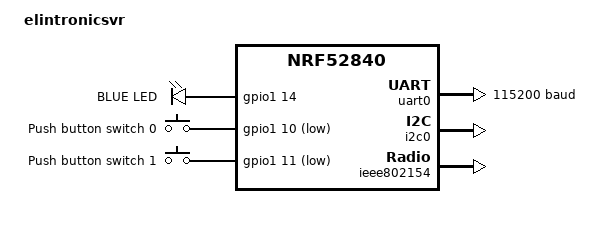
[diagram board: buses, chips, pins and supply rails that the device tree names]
// Copyright (c) 2023 Nordic Semiconductor ASA
// SPDX-License-Identifier: Apache-2.0

/dts-v1/;
#include <nordic/nrf52840_qiaa.dtsi>
#include "elintronicsvr-pinctrl.dtsi"

/ {
	model = "elintronicsvr";
	compatible = "elintronicsvr";

	chosen {
		zephyr,sram = &sram0;
		zephyr,flash = &flash0;
		zephyr,code-partition = &slot0_partition;
		zephyr,console = &uart0;
		zephyr,shell-uart = &uart0;
		zephyr,uart-mcumgr = &uart0;
		zephyr,bt-mon-uart = &uart0;
		zephyr,bt-c2h-uart = &uart0;
		zephyr,ieee802154 = &ieee802154;
	};

	leds {
		compatible = "gpio-leds";
		ledblue: led_0 {
			gpios = <&gpio1 14 0>;
			label = "BLUE LED";
		};
	};

	buttons {
		compatible = "gpio-keys";
		button0: button_0 {
			gpios = <&gpio1 10 (GPIO_PULL_UP | GPIO_ACTIVE_LOW)>;
			label = "Push button switch 0";
		};
		button1: button_1 {
			gpios = <&gpio1 11 (GPIO_PULL_UP | GPIO_ACTIVE_LOW)>;
			label = "Push button switch 1";
		};
	};

	aliases {
		ledblue = &ledblue;	
		button0 = &button0;	
	};
};

&gpiote {
	status = "okay";
};

&gpio0 {
	status = "okay";
};

&gpio1 {
	status = "okay";
};

&uart0 {
	compatible = "nordic,nrf-uarte";
	status = "okay";
	current-speed = <115200>;
	pinctrl-0 = <&uart0_default>;
	pinctrl-1 = <&uart0_sleep>;
	pinctrl-names = "default", "sleep";
};

&i2c0 {
	compatible = "nordic,nrf-twi";
	status = "okay";
	pinctrl-0 = <&i2c0_default>;
	pinctrl-1 = <&i2c0_sleep>;
	pinctrl-names = "default", "sleep";
};


&flash0 {
	partitions {
		compatible = "fixed-partitions";
		#address-cells = <1>;
		#size-cells = <1>;

		boot_partition: partition@0 {
			label = "mcuboot";
			reg = <0x0 0xc000>;
		};
		slot0_partition: partition@c000 {
			label = "image-0";
			reg = <0xc000 0x72000>;
		};
		slot1_partition: partition@7e000 {
			label = "image-1";
			reg = <0x7e000 0x72000>;
		};
		scratch_partition: partition@f0000 {
			label = "image-scratch";
			reg = <0xf0000 0xa000>;
		};
		storage_partition: partition@fa000 {
			label = "storage";
			reg = <0xfa000 0x6000>;
		};
	};
};

&ieee802154 {
	status = "okay";
};

